# EMIF1 register map
Vendor: Texas Instruments
Peripheral module from a debugger description file (folder omap5430_ES2_PUBLIC).
Registers are 32-bit, read-write, reset 0x0 unless marked. A register's access mark holds for its fields unless they carry their own. Offsets are as the file gives them; lines under a group give offsets from that group; [hi:lo] are bit positions; {n}, {i} and the like mark numbered series; 'fields as' and 'values as' point back to an identical list; <NAME> marks a mode.

## EMIF1 (part 1 of 2)
0x00 EMIF_REVISION ro reset not defined — Revision number register
  [31:0] REVISION — Module revision
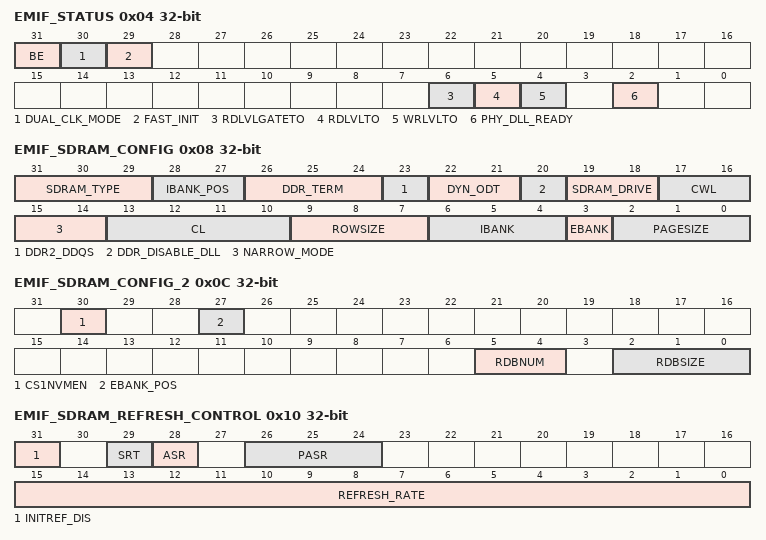
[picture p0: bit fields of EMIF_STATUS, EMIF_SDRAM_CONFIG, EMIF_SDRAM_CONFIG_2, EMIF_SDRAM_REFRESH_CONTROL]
0x04 EMIF_STATUS ro — SDRAM Status Register (STATUS)
  [31] BE — Big endian mode select for 8 and 16-bit devices, set to 1 for big endian or 0 for little endian operation. In current implementation, only 32-bit devices are supported - this bit is don't care.
  [30] DUAL_CLK_MODE — Dual Clock mode. Defines whether the EMIFi_L3_ICLK and EMIF_COREi clock are asynchronous. EMIFi_L3_ICLK and EMIF_COREi clock are asynchronous, if set to 1.
  [29] FAST_INIT — Fast Init. Defines whether the EMIF fast initialization mode has been enabled. Fast initialization is enabled if set to 1.
  [6] RDLVLGATETO — Read DQS Gate Training Timeout. Value of 1 indicates read DQS gate training has timed out because read DQS gate training done was not received from the PHY.
  [5] RDLVLTO — Read Data Eye Training Timeout. Value of 1 indicates read data eye training has timed out because read data eye training done was not received from the PHY.
  [4] WRLVLTO — Write Leveling Timeout. Value of 1 indicates write leveling has timed out because write leveling done was not received from the PHY.
  [2] PHY_DLL_READY — DDR PHY Ready. The DDR PHY is ready for normal operation, if set to 1.
0x08 EMIF_SDRAM_CONFIG — SDRAM Config Register. A write to this register will cause the EMIF to start the SDRAM initialization sequence. For LPDDR2, initialization is only re-started if it was not performed previously because [31] INITREF_DIS was a zero. CAUTION: This register is loaded with values by control module at device reset.
  [31:29] SDRAM_TYPE — SDRAM Type selection. This field is loaded from e-fuse. Set to 3 for DDR3 Set to 4 for LPDDR2 All other values are reserved.
  [28:27] IBANK_POS — Internal bank position. See section , .
  [26:24] DDR_TERM — DDR3 termination resistor value. Set to 0 to disable termination. For DDR3, set to 1 for RZQ/4, set to 2 for RZQ/2, set to 3 for RZQ/6, set to 4 for RZQ/12, and set to 5 for RZQ/8. All other values are reserved.
  [23] DDR2_DDQS — DDR2 differential DDQS enable. NOT SUPPORTED. Set to 1 for compatibility.
  [22:21] DYN_ODT — DDR3 Dynamic ODT. NOT SUPPORTED. Set to 0 to turn off dynamic ODT.
  [20] DDR_DISABLE_DLL — Disable DLL select. Set to 1 to disable DLL inside SDRAM.
  [19:18] SDRAM_DRIVE — SDRAM drive strength.For DDR3, set to 0 for RZQ/6 and set to 1 for RZQ/7. All other values are reserved.
  [17:16] CWL — DDR3 CAS Write latency. Value of 0, 1, 2, and 3 (CAS write latency of 5, 6, 7, and 8) are supported. Use the lowest value supported for best performance. All other values are reserved.
  [15:14] NARROW_MODE — SDRAM data bus width. Set to 0 for 32-bit and set to 1 for 16-bit. All other values are reserved. In the current implementation, only 32-bit devices are supported. Two DDR3 devices are used in parallel to make one 32-bit device.
  [13:10] CL — CAS Latency (referred to as read latency (RL) in some SDRAM specs). The value of this field defines the CAS latency to be used when accessing connected SDRAM devices. Values of 3, 4, 5, 6, 7, and 8 (CAS latency of 3, 4, 5, 6, 7, and 8) are supported for LPDDR2-SDRAM. Values of 2, 4, 6, 8, 10, 12, and 14 (CAS latency of 5, 6, 7, 8, 9, 10, and 11) are supported for DDR3. All other values are reserved. The write latency (WL) is tied to the RL for the LPDDR2. See the LPDDR2 SDRAM standard. Also program the EMIF_DDR_PHY_CONTROL_1[4:0] READ_LATENCY
  [9:7] ROWSIZE — Row Size. Defines the number of row address bits of connected SDRAM devices. Set to 0 for 9 row bits, Set to 1 for 10 row bits, Set to 2 for 11 row bits, Set to 3 for 12 row bits, Set to 4 for 13 row bits, Set to 5 for 14 row bits, Set to 6 for 15 row bits, Set to 7 for 16 row bits. This field is only used when EMIF_SDRAM_CONFIG[28:27] IBANK_POS field is set to 1, 2, or 3 or EBANK_POS field in EMIF_SDRAM_CONFIG_2 register is set to 1.
  [6:4] IBANK — Internal Bank setup. Defines number of banks inside connected SDRAM devices. Set to 0 for 1 bank, Set to 1 for 2 banks, Set to 2 for 4 banks, Set to 3 for 8 banks. All other values are reserved.
  [3] EBANK — External chip select setup. Defines whether SDRAM accesses will use 1 or 2 chip select lines. Set to 0 to use NCS0 only. Set to 1 to use NCS[1:0]. This bit will automatically be set to 0 if EMIF_SDRAM_CONFIG_2[30] CS1NVMEN field is set to 1.
  [2:0] PAGESIZE — Page Size. Defines the internal page size of connected SDRAM devices. Set to 0 for 256-word page (8 column bits), Set to 1 for 512-word page (9 column bits), Set to 2 for 1024-word page (10 column bits), Set to 3 for 2048-word page (11 column bits). All other values are reserved.
0x0C EMIF_SDRAM_CONFIG_2 access per field — SDRAM Config Register 2 CAUTION: This register is loaded with values by control module at device reset.
  [30] CS1NVMEN rw — CS1 LPDDR2-NVM enable. NVMs are not supported at device level.
  [27] EBANK_POS rw — External bank position. Set to 0 to assign external bank address bits from lower OCP address. Set to 1 to assign external bank address bits from higher OCP address bits. See section, .
  [5:4] RDBNUM rw — Row Buffer setup. Defines number of row buffers inside connected LPDDR2-NVM devices. NVM devices are not supported at the device level. Set to 0 for 1 row buffer, set to 1 for 2 row buffers, set to 2 for 4 row buffers, and set to 3 for 8 row buffers. All other values are reserved.
  [2:0] RDBSIZE rw — Row Data Buffer Size. Defines the row data buffer size of connected LPDDR2-NVM devices. NVM devices are not supported at the device level. Set to 0 for 32 bytes, set to 1 for 64 bytes, set to 2 for 128 bytes, set to 3 for 256 bytes, set to 4 for 512 bytes, set to 5 for 1024 bytes, set to 6 for 2048 bytes, and set to 7 for 4096 bytes.
0x10 EMIF_SDRAM_REFRESH_CONTROL access per field — SDRAM Refresh Control Register
  [31] INITREF_DIS rw — Initialization and Refresh disable. When set to 1, EMIF will disable SDRAM initialization and refreshes, but will carry out SDRAM write/read transactions.
  [29] SRT rw — DDR3 Self Refresh temperature range. Set to 0 for normal operating temperature range and set to 1 for extended operating temperature range when the ASR field is set to 0. This bit must be set to 0 if the ASR field is set to 1. A write to this field will cause the EMIF to start the SDRAM initialization sequence.
  [28] ASR rw — DDR3 Auto Self Refresh enable. Set to 1 for auto Self Refresh enable. Set to 0 for manual Self Refresh reference indicated by the SRT field. A write to this field will cause the EMIF to start the SDRAM initialization sequence.
  [26:24] PASR rw — Partial Array Self Refresh. These bits get loaded into the Extended Mode Register of DDR3 during initialization. For DDR3, set to 0 for full array, set to 1 or 5 for 1/2 array, set to 2 or 6 for 1/4 array, set to 3 or 7 for 1/8 array, and set to 4 for 3/4 array to be refreshed. All other values are reserved. A write to this field will cause the EMIF to start the SDRAM initialization sequence.
  [15:0] REFRESH_RATE rw — Refresh Rate. Value in this field is used to define the rate at which connected SDRAM devices will be refreshed. SDRAM refresh rate = REFRESH_RATE / EMIFi_PHY_FICLK. A 533-MHz DDR clock rate system that requires a 7.8 µs refresh rate would need 7.8 × 533 = 4157 or 0x103D value to be written. To avoid lock-up situations, the programmer must not program REFRESH_RATE &lt; (6 × EMIF_SDRAM_TIMING_3[12:4] T_RFC).
0x14 EMIF_SDRAM_REFRESH_CONTROL_SHADOW access per field — SDRAM Refresh Control Shadow Register
  [15:0] REFRESH_RATE_SHDW rw — Shadow field for REFRESH_RATE. This field is loaded intoEMIF_SDRAM_REFRESH_CONTROL[15:0] REFRESH_RATE field when SIdleAck is asserted.
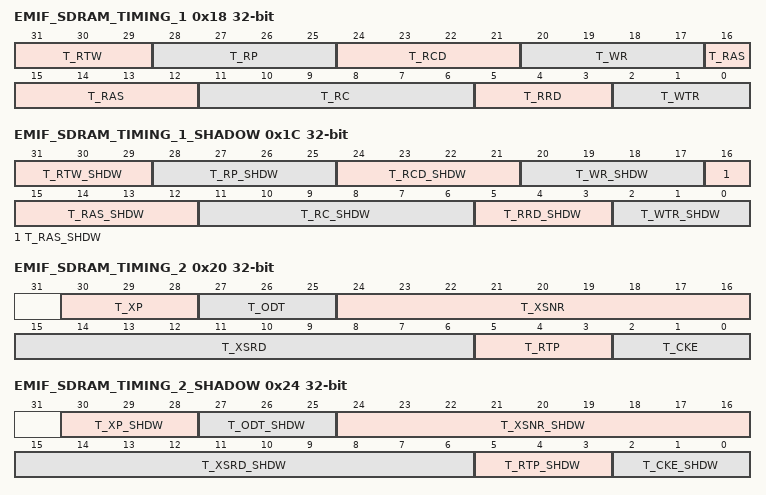
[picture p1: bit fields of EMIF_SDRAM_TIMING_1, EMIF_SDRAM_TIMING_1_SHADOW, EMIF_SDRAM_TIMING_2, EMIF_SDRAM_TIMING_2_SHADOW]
0x18 EMIF_SDRAM_TIMING_1 — SDRAM Timing 1 Register. If this register is byte written, care must be taken that all the fields are written before performing any accesses to the SDRAM.
  [31:29] T_RTW — Minimum number of DDR clock cycles between Read to Write data phases, minus one.
  [28:25] T_RP — Minimum number of DDR clock cycles from Precharge to Activate or Refresh, minus one.
  [24:21] T_RCD — Minimum number of DDR clock cycles from Activate to Read or Write, minus one.
  [20:17] T_WR — Minimum number of DDR clock cycles from last Write transfer to Precharge, minus one.
  [16:12] T_RAS — Minimum number of DDR clock cycles from Activate to Precharge, minus one. T_RAS value needs to be bigger than or equal to T_RDC value.
  [11:6] T_RC — Minimum number of DDR clock cycles from Activate to Activate, minus one.
  [5:3] T_RRD — Minimum number of DDR clock cycles from Activate to Activate for a different bank, minus one. For an 8-bank, this field must be equal to ((tFAW / (4 × tCK)) - 1).
  [2:0] T_WTR — Minimum number of DDR clock cycles from last Write to Read, minus one.
0x1C EMIF_SDRAM_TIMING_1_SHADOW — SDRAM Timing 1 Shadow Register
  [31:29] T_RTW_SHDW — Shadow field for T_RTW. This field is loaded intoEMIF_SDRAM_TIMING_1[31:29] T_RTW field when SIdleAck is asserted.
  [28:25] T_RP_SHDW — Shadow field for T_RP. This field is loaded intoEMIF_SDRAM_TIMING_1[28:25] T_RP field when SIdleAck is asserted.
  [24:21] T_RCD_SHDW — Shadow field for T_RCD. This field is loaded intoEMIF_SDRAM_TIMING_1[24:21] T_RCD field when SIdleAck is asserted.
  [20:17] T_WR_SHDW — Shadow field for T_WR. This field is loaded intoEMIF_SDRAM_TIMING_1[20:17] T_WR field when SIdleAck is asserted.
  [16:12] T_RAS_SHDW — Shadow field for T_RAS. This field is loaded intoEMIF_SDRAM_TIMING_1[16:12] T_RAS field when SIdleAck is asserted.
  [11:6] T_RC_SHDW — Shadow field for T_RC. This field is loaded intoEMIF_SDRAM_TIMING_1[11:6] T_RC field when SIdleAck is asserted.
  [5:3] T_RRD_SHDW — Shadow field for T_RRD. This field is loaded intoEMIF_SDRAM_TIMING_1[5:3] T_RRD field when SIdleAck is asserted.
  [2:0] T_WTR_SHDW — Shadow field for T_WTR. This field is loaded intoEMIF_SDRAM_TIMING_1[2:0] T_WTR field when SIdleAck is asserted.
0x20 EMIF_SDRAM_TIMING_2 access per field — SDRAM Timing 2 Register. If this register is byte written, care must be taken that all the fields are written before performing any accesses to the SDRAM.
  [30:28] T_XP rw — Minimum number of DDR clock cycles from power-down exit to any command other than a read command, minus one.
  [27:25] T_ODT rw — Minimum number of DDR clock cycles from ODT enable to write data driven for DDR3. Must be equal to tAOND.
  [24:16] T_XSNR rw — Minimum number of DDR clock cycles from Self-Refresh exit to any command other than a Read command, minus one. For LPDDR2, T_XSNR and T_XSRD must be programmed with the same value (tXSR). For DDR3, the value of tXS must be programmed.
  [15:6] T_XSRD rw — Minimum number of DDR clock cycles from Self-Refresh exit to a Read command, minus one. For LPDDR2, T_XSNR and T_XSRD must be programmed with the same value (tXSR). For DDR3, the value of tXSDLL must be programmed.
  [5:3] T_RTP rw — Minimum number of DDR clock cycles for the last read command to a Precharge command, minus one.
  [2:0] T_CKE rw — Minimum number of DDR clock cycles between CKE pin changes, minus one.
0x24 EMIF_SDRAM_TIMING_2_SHADOW access per field — SDRAM Timing 2 Shadow Register
  [30:28] T_XP_SHDW rw — Shadow field for T_XP. This field is loaded intoEMIF_SDRAM_TIMING_2[30:28] T_XP field when SIdleAck is asserted.
  [27:25] T_ODT_SHDW rw — Shadow field for T_ODT. This field is loaded into T_ODT field in SDRAM Timing 2 register when SIdleAck is asserted.
  [24:16] T_XSNR_SHDW rw — Shadow field for T_XSNR. This field is loaded intoEMIF_SDRAM_TIMING_2[24:16] T_XSNR field when SIdleAck is asserted.
  [15:6] T_XSRD_SHDW rw — Shadow field for T_XSRD. This field is loaded intoEMIF_SDRAM_TIMING_2[15:6] T_XSRD field when SIdleAck is asserted.
  [5:3] T_RTP_SHDW rw — Shadow field for T_RTP. This field is loaded intoEMIF_SDRAM_TIMING_2[5:3] T_RTP field when SIdleAck is asserted.
  [2:0] T_CKE_SHDW rw — Shadow field for T_CKE. This field is loaded intoEMIF_SDRAM_TIMING_2[2:0] T_CKE field when SIdleAck is asserted.
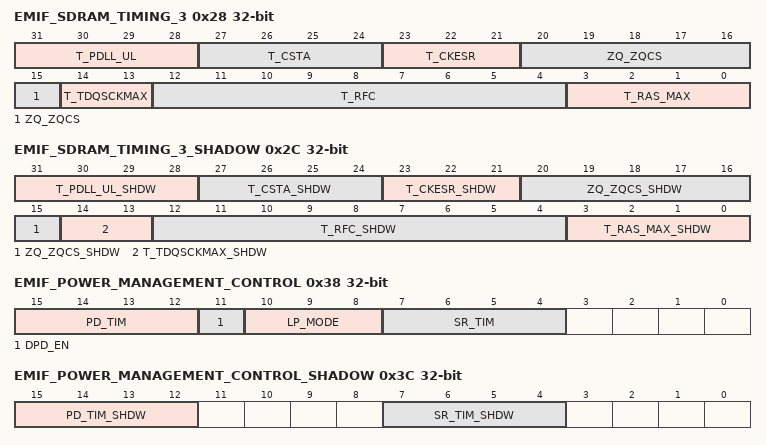
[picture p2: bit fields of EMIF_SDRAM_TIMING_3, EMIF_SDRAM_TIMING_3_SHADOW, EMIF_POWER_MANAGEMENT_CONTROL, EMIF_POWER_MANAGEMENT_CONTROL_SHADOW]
0x28 EMIF_SDRAM_TIMING_3 — SDRAM Timing 3 Register. If this register is byte written, care must be taken that all the fields are written before performing any accesses to the SDRAM.
  [31:28] T_PDLL_UL — Minimum number of DDR clock cycles for PHY DLL to unlock. A value of N will be equal to N x 128 clocks.
  [27:24] T_CSTA — Minimum number of DDR clock cycles between write-to-write or read-to-read data phases to different chip selects, minus one.
  [23:21] T_CKESR — Minimum number of DDR clock cycles for which SDRAM must remain in Self Refresh, minus one.
  [20:15] ZQ_ZQCS — Number of DDR clock cycles for a ZQCS command, minus one.
  [14:13] T_TDQSCKMAX — Number of DDR clock that satisfies tDQSCKmax for LPDDR2, minus one.
  [12:4] T_RFC — Minimum number of DDR clock cycles from Refresh or Load Mode to Refresh or Activate, minus one.
  [3:0] T_RAS_MAX — Maximum number of REFRESH_RATE intervals from Activate to Precharge command. This field must be equal to ((tRASmax / tREFI)-1) rounded down to the next lower integer. Value for T_RAS_MAX can be calculated as follows: If tRASmax = 120 us and tREFI = 15.7 us, then T_RAS_MAX = ((120/15.7)-1) = 6.64. Round down to the next lower integer. Therefore, the programmed value must be 6.
0x2C EMIF_SDRAM_TIMING_3_SHADOW — SDRAM Timing 3 Shadow Register
  [31:28] T_PDLL_UL_SHDW — Shadow field for T_PDLL_UL. This field is loaded into T_PDLL_UL field inEMIF_SDRAM_TIMING_3 register when SIdleAck is asserted.
  [27:24] T_CSTA_SHDW — Shadow field for T_CSTA. This field is loaded into T_CSTA field inEMIF_SDRAM_TIMING_3 register when SIdleAck is asserted.
  [23:21] T_CKESR_SHDW — Shadow field for T_CKESR. This field is loaded into T_CKESR field inEMIF_SDRAM_TIMING_3 register when SIdleAck is asserted.
  [20:15] ZQ_ZQCS_SHDW — Shadow field for ZQ_ZQCS. This field is loaded into ZQ_ZQCS field inEMIF_SDRAM_TIMING_3 register when SIdleAck is asserted.
  [14:13] T_TDQSCKMAX_SHDW — Shadow field for T_TDQSCKMAX. This field is loaded intoEMIF_SDRAM_TIMING_3[14:13] T_TDQSCKMAX field when SIdleAck is asserted.
  [12:4] T_RFC_SHDW — Shadow field for T_RFC. This field is loaded intoEMIF_SDRAM_TIMING_3[12:4] T_RFC when SIdleAck is asserted.
  [3:0] T_RAS_MAX_SHDW — Shadow field for T_RAS_MAX. This field is loaded intoEMIF_SDRAM_TIMING_3[3:0] T_RAS_MAX field when SIdleAck is asserted.
0x38 EMIF_POWER_MANAGEMENT_CONTROL access per field — Power Management Control Register. Updating the *_TIM fields must be followed by at least one access to SDRAM for the new value to take an effect.
  [15:12] PD_TIM rw — Power Management timer for Power-Down. The EMIF will put the external SDRAM in Power-Down mode after the EMIF is idle for these number of DDR clock cycles and if LP_MODE field is set to 4. Set to 0 to immediately enter Power-Down mode. Set to 1 for 16 clocks, set to 2 for 32 clocks, set to 3 for 64 clocks, set to 4 for 128 clocks, set to 5 for 256 clocks, set to 6 for 512 clocks, set to 7 for 1024 clocks, set to 8 for 2048 clocks, set to 9 for 4096 clocks, set to 10 for 8192 clocks, set to 11 for 16384 clocks, set to 12 for 32768 clocks, set to 13 for 65536 clocks, set to 14 for 131072 clocks, and set to 15 for 262144 clocks.
  [11] DPD_EN rw — Deep Power Down enable. Set to 0 for normal operation. Set to 1 to enter deep power-down mode. This mode will override the LP_MODE field setting.
  [10:8] LP_MODE rw — Automatic Power Management enable. Set to 1 for Clock Stop (reserved for the not supported LPDDR1 memories), set to 2 for Self Refresh mode, and set to 4 for Power-Down mode. All other values will disable automatic power management.
  [7:4] SR_TIM rw — Power Management timer for Self Refresh. The EMIF will put the external SDRAM in Self Refresh mode after the EMIF is idle for these number of DDR clock cycles and if LP_MODE field is set to 2. Set to 0 to immediately enter Self Refresh mode. Set to 1 for 16 clocks, set to 2 for 32 clocks, set to 3 for 64 clocks, set to 4 for 128 clocks, set to 5 for 256 clocks, set to 6 for 512 clocks, set to 7 for 1024 clocks, set to 8 for 2048 clocks, set to 9 for 4096 clocks, set to 10 for 8192 clocks, set to 11 for 16384 clocks, set to 12 for 32768 clocks, set to 13 for 65536 clocks, set to 14 for 131072 clocks, and set to 15 for 262144 clocks.
0x3C EMIF_POWER_MANAGEMENT_CONTROL_SHADOW access per field — Power Management Control Shadow Register
  [15:12] PD_TIM_SHDW rw — Shadow field for PD_TIM. This field is loaded into PD_TIM field inEMIF_POWER_MANAGEMENT_CONTROL register when SIdleAck is asserted.
  [7:4] SR_TIM_SHDW rw — Shadow field for SR_TIM. This field is loaded into SR_TIM field inEMIF_POWER_MANAGEMENT_CONTROL register when SIdleAck is asserted.
0x40 EMIF_LPDDR2_MODE_REG_DATA access per field — LPDDR2 Mode Reg Data Register A write to this register will cause a Mode Register write command to be sent to the LPDDR2 device with write data as specified in the VALUE_0 field. The address and chip select are taken from the register. A read to this register will cause a Mode Register read command to be sent to the LPDDR2 device. The address and chip select are taken from the register. The read data will appear in VALUE_0 field.
  [6:0] VALUE_0 rw — Mode register value.
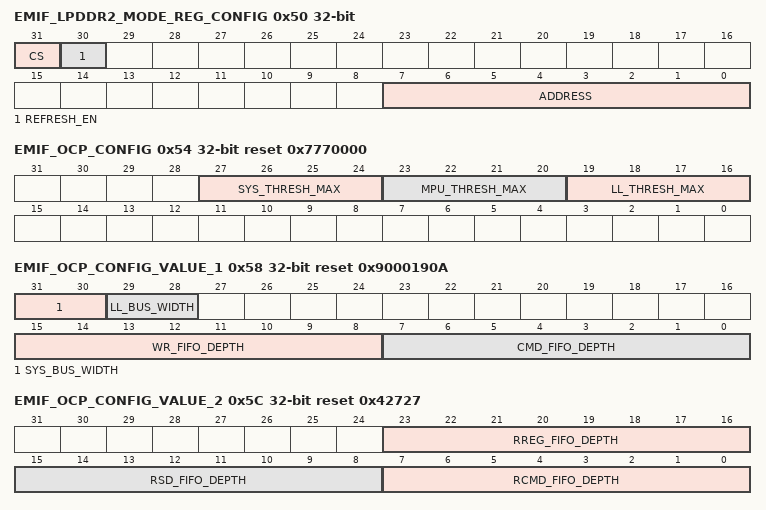
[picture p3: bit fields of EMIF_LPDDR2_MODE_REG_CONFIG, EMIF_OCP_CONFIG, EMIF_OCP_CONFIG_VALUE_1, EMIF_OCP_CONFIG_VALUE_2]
0x50 EMIF_LPDDR2_MODE_REG_CONFIG access per field — LPDDR2 Mode Reg Config Register
  [31] CS rw — Chip select to issue mode register command. Set to 0 for CS0 and set to 1 for CS1.
  [30] REFRESH_EN rw — Refresh Enable after MRW write. If aEMIF_LPDDR2_MODE_REG_DATA register write occurs with this bit set to 1, the refresh operations will commence.
  [7:0] ADDRESS rw — Mode register address.
0x54 EMIF_OCP_CONFIG access per field reset 0x7770000 — OCP Config Register
  [27:24] SYS_THRESH_MAX rw — System OCP Threshold Maximum. The number of commands the system interface can consume in the command FIFO. The value is used to determine when to stop future request, writing a zero will reserve no space for the associated interface. In the event the value is set to zero and a request is seen for that interface, the command FIFO will assume a value of 1. Since the low-latency interface has effectively a higher priority, the only way for the system interface to use all command FIFO entries is to set the LL_THRESH_MAX to zero.
  [23:20] MPU_THRESH_MAX rw — MPU Threshold Maximum. The number of commands the MPU interface can consume in the command FIFO. The value is used to determine when to stop future request, writing a zero will reserve no space for the associated interface. In the event the value is set to zero and a request is seen for that interface, the command FIFO will assume a value of 1. Since the low-latency interface has effectively a higher priority, the only way for the MPU interface to use all command FIFO entries is to set the LL_THRESH_MAX to zero.
  [19:16] LL_THRESH_MAX rw — Low-latency OCP Threshold Maximum. The number of commands the low latency interface can consume in the command FIFO. The value is used to determine when to stop future request, writing a zero will reserve no space for the associated interface. In the event the value is set to zero and a request is seen for that interface, the command FIFO will assume a value of 1.
0x58 EMIF_OCP_CONFIG_VALUE_1 ro reset 0x9000190A — OCP Config Value 1 Register
  [31:30] SYS_BUS_WIDTH — System OCP data bus width 0 = 32-bit wide, 1 = 64-bit wide, 2 = 128-bit wide, 3 = Reserved
  [29:28] LL_BUS_WIDTH — Low-latency OCP data bus width 0 = 32-bit wide, 1 = 64-bit wide, 2 = 128-bit wide, 3 = Reserved
  [15:8] WR_FIFO_DEPTH — Write Data FIFO depth
  [7:0] CMD_FIFO_DEPTH — Command FIFO depth
0x5C EMIF_OCP_CONFIG_VALUE_2 ro reset 0x42727 — OCP Config Value 2 Register
  [23:16] RREG_FIFO_DEPTH — Register Read Data FIFO depth
  [15:8] RSD_FIFO_DEPTH — SDRAM Read Data FIFO depth
  [7:0] RCMD_FIFO_DEPTH — Read Command FIFO depth
0x80 EMIF_PERFORMANCE_COUNTER_1 ro — Performance Counter 1 Register
  [31:0] COUNTER1 — 32-bit counter that can be configured as specified in theEMIF_PERFORMANCE_COUNTER_CONFIG register and EMIF_PERFORMANCE_COUNTER_MASTER_REGION_SELECT register.
0x84 EMIF_PERFORMANCE_COUNTER_2 ro — Performance Counter 2 Register
  [31:0] COUNTER2 — 32-bit counter that can be configured as specified in theEMIF_PERFORMANCE_COUNTER_CONFIG register and EMIF_PERFORMANCE_COUNTER_MASTER_REGION_SELECT register.
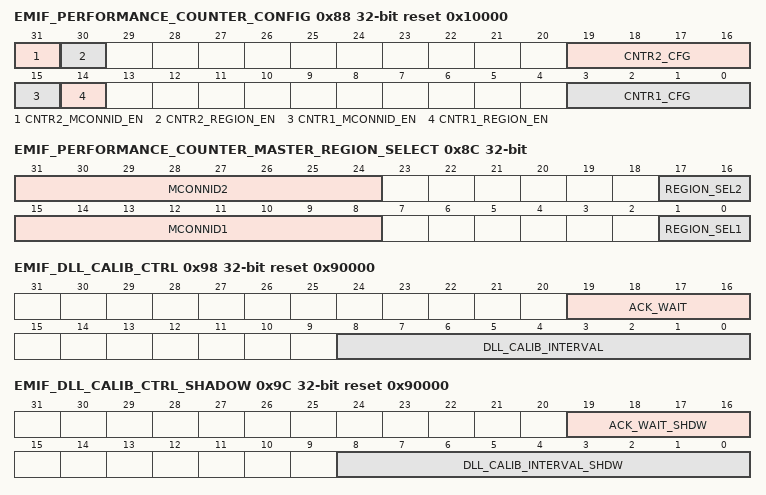
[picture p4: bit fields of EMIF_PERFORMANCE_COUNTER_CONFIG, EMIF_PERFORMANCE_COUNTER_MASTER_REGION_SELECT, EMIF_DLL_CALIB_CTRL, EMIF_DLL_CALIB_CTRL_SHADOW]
0x88 EMIF_PERFORMANCE_COUNTER_CONFIG access per field reset 0x10000 — Performance Counter Config Register
  [31] CNTR2_MCONNID_EN rw — MConnID filter enable forEMIF_PERFORMANCE_COUNTER_2 register.
  [30] CNTR2_REGION_EN rw — Chip Select filter enable forEMIF_PERFORMANCE_COUNTER_2 register.
  [19:16] CNTR2_CFG rw — Filter configuration forEMIF_PERFORMANCE_COUNTER_2. Refer to for details.
  [15] CNTR1_MCONNID_EN rw — MConnID filter enable forEMIF_PERFORMANCE_COUNTER_1 register.
  [14] CNTR1_REGION_EN rw — Chip Select filter enable forEMIF_PERFORMANCE_COUNTER_1 register.
  [3:0] CNTR1_CFG rw — Filter configuration forEMIF_PERFORMANCE_COUNTER_1. Refer to for details.
0x8C EMIF_PERFORMANCE_COUNTER_MASTER_REGION_SELECT access per field — Performance Counter Master Region Select Register The values programmed into the MCONNIDx fields are those in Table ConnID Mapping (Debug View), in , On-Chip Debug Support, left-shifted by 2 bits. For example, to monitor accesses from the IPU subsystem (ConnID = 0x11), the value 0x44 is programmed into the MCONNIDx field.
  [31:24] MCONNID2 rw — MConnID forEMIF_PERFORMANCE_COUNTER_2 register.
  [17:16] REGION_SEL2 rw — MAddrSpace forEMIF_PERFORMANCE_COUNTER_2 register.
  [15:8] MCONNID1 rw — MConnID forEMIF_PERFORMANCE_COUNTER_1 register.
  [1:0] REGION_SEL1 rw — MAddrSpace forEMIF_PERFORMANCE_COUNTER_1 register.
0x90 EMIF_PERFORMANCE_COUNTER_TIME ro — Performance Counter Time Register. This is a free running counter.
  [31:0] TOTAL_TIME — 32-bit counter that continuously counts number for EMIF_COREi clock cycles elapsed after EMIF is brought out of reset.
0x94 EMIF_MISC_REG access per field
  [0] DLL_CALIB_OS rw — Phy_dll_calib one shot : Setting bit to 1 generates a phy_pll_calib pulse. Bit is self cleared when pll_calib gets generated and ack_wait has been satisfied. Software can poll to confirm completion. Uses the EMIF_DLL_CALIB_CTRL[19:16] ACK_WAIT bit field for time to wait after firing off the phy_dll_calib.
0x98 EMIF_DLL_CALIB_CTRL access per field reset 0x90000 — Control register to force idle window time to generate a phy_dll_calib that can be used for updating PHY DLLs during voltage ramps. NOTE: Should always be loaded via the shadow register.
  [19:16] ACK_WAIT rw — The ack_wait determines the required wait time after a phy_dll_calib is generated before another command can be sent. Value program is in terms of EMIF_COREi cycle count. 5 must be the minimum value ever programmed.
  [8:0] DLL_CALIB_INTERVAL rw — This field determines the interval between phy_dll_calib generation. This value is multiplied by a precounter of 16 EMIF_COREi cycles. Program this field one less the value you are targeting; program 1 to achieve interval of 2 (minimum interval supported). Programming zero turns off function. Note the final intervals between dll_calib generation is also a function of ACK_WAIT. Final periodic interval is calculated by: ((DLL_CALIB_INTERVAL + 1) × 16) + ACK_WAIT
0x9C EMIF_DLL_CALIB_CTRL_SHADOW access per field reset 0x90000 — Read Idle Control Shadow Register
  [19:16] ACK_WAIT_SHDW rw — Shadow field for ACK_WAIT. This field is loaded into ACK_WAIT field inEMIF_DLL_CALIB_CTRL register when SIdleAck is asserted
  [8:0] DLL_CALIB_INTERVAL_SHDW rw — Shadow field for DLL_CALIB_INTERVAL. This field is loaded into DLL_CALIB_INTERVAL field in theEMIF_DLL_CALIB_CTRL register when SIdleAck is asserted
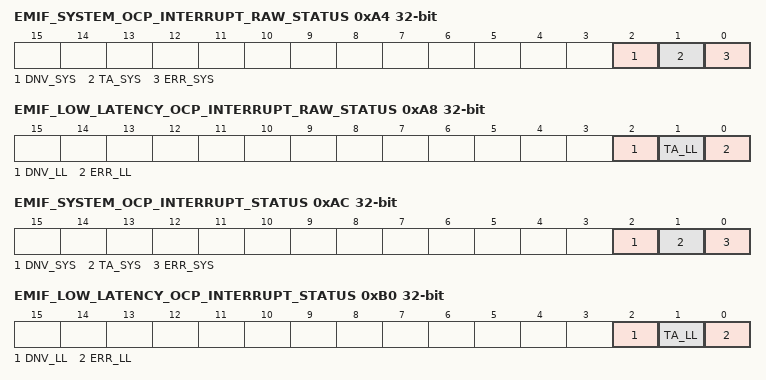
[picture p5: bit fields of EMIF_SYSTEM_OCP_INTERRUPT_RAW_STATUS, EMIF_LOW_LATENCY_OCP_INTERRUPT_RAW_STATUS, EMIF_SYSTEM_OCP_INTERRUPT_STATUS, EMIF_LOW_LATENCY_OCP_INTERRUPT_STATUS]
0xA4 EMIF_SYSTEM_OCP_INTERRUPT_RAW_STATUS access per field — System OCP Interrupt Raw Status Register
  [2] DNV_SYS rw — Raw status of system OCP interrupt for LPDDR2 NVM data not valid. Write 1 to set the (raw) status, typically for debug. Writing 0 has no effect.
  [1] TA_SYS rw — Raw status of system OCP interrupt for SDRAM temperature alert. Write 1 to set the (raw) status, mostly for debug. Writing a 0 has no effect.
  [0] ERR_SYS rw — Raw status of system OCP interrupt for command or address error. Write 1 to set the (raw) status, mostly for debug. Writing a 0 has no effect.
0xA8 EMIF_LOW_LATENCY_OCP_INTERRUPT_RAW_STATUS access per field — Low-Latency OCP Interrupt Raw Status Register
  [2] DNV_LL rw — Raw status of low-latency OCP interrupt for LPDDR2 NVM data not valid. Write 1 to set the (raw) status, typically for debug. Writing 0 has no effect.
  [1] TA_LL rw — Raw status of low-latency OCP interrupt or SDRAM temperature alert. Write 1 to set the (raw) status, mostly for debug. Writing a 0 has no effect.
  [0] ERR_LL rw — Raw status of low-latency OCP interrupt for command or address error. Write 1 to set the (raw) status, mostly for debug. Writing a 0 has no effect.
0xAC EMIF_SYSTEM_OCP_INTERRUPT_STATUS access per field — System OCP Interrupt Status Register
  [2] DNV_SYS rw — Enabled status of system OCP interrupt for LPDDR2 NVM data not valid. Write 1 to clear the status after interrupt is serviced (raw status is cleared; that is, even if not enabled). Writing 0 has no effect.
  [1] TA_SYS rw — Enabled status of system OCP interrupt for SDRAM temperature alert. Write 1 to clear the status after interrupt has been serviced (raw status gets cleared, that is, even if not enabled). Writing a 0 has no effect.
  [0] ERR_SYS rw — Enabled status of system OCP interrupt interrupt for command or address error. Write 1 to clear the status after interrupt has been serviced (raw status gets cleared, that is, even if not enabled). Writing a 0 has no effect.
0xB0 EMIF_LOW_LATENCY_OCP_INTERRUPT_STATUS access per field — Low-Latency OCP Interrupt Status Register
  [2] DNV_LL rw — Enabled status of low-latency OCP interrupt for LPDDR2 NVM data not valid. Write 1 to clear the status after interrupt is serviced (raw status is cleared; that is, even if not enabled). Writing 0 has no effect.
  [1] TA_LL rw — Enabled status of low-latency OCP interrupt for SDRAM temperature alert. Write 1 to clear the status after interrupt has been serviced (raw status gets cleared, that is, even if not enabled). Writing a 0 has no effect.
  [0] ERR_LL rw — Enabled status of low-latency OCP interrupt for command or address error. Write 1 to clear the status after interrupt has been serviced (raw status gets cleared, that is, even if not enabled). Writing a 0 has no effect.
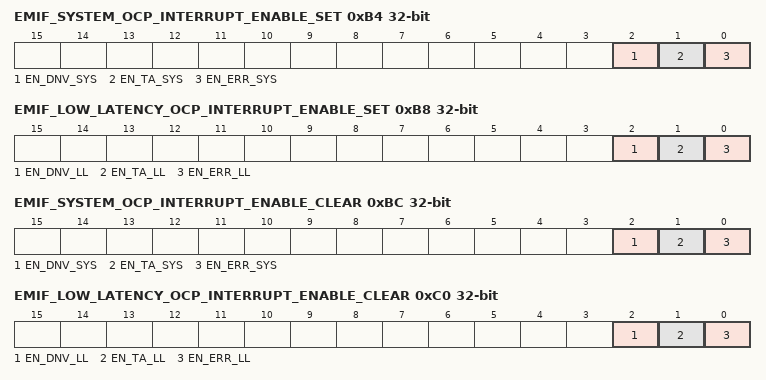
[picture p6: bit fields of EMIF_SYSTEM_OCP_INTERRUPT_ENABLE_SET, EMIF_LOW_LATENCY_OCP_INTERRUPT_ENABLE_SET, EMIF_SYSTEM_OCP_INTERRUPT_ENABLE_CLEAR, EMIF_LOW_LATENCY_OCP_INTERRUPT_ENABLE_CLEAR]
0xB4 EMIF_SYSTEM_OCP_INTERRUPT_ENABLE_SET access not given — System OCP Interrupt Enable Set Register
  [2] EN_DNV_SYS — Enable set for system OCP interrupt for LPDDR2 NVM data not valid. Writing 1 enables the interrupt and sets this bit and the corresponding Interrupt-enable clear register. Writing 0 has no effect. (access RW W1toSet)
  [1] EN_TA_SYS — Enable set for system OCP interrupt for SDRAM temperature alert. . Writing a 1 will enable the interrupt, and set this bit as well as the corresponding Interrupt Enable Clear Register. Writing a 0 has no effect. (access RW W1toSet)
  [0] EN_ERR_SYS — Enable set for system OCP interrupt for command or address error. Writing a 1 will enable the interrupt, and set this bit as well as the corresponding Interrupt Enable Clear Register. Writing a 0 has no effect. (access RW W1toSet)
0xB8 EMIF_LOW_LATENCY_OCP_INTERRUPT_ENABLE_SET access not given — Low-Latency OCP Interrupt Enable Set Register
  [2] EN_DNV_LL — Enable set for low-latency OCP interrupt for LPDDR2 NVM data not valid. Writing 1 enables the interrupt and sets this bit and the corresponding Interrupt-enable clear register. Writing a 0 has no effect. (access RW W1toSet)
  [1] EN_TA_LL — Enable set for low-latency OCP interrupt for SDRAM temperature alert. Writing a 1 will enable the interrupt, and set this bit as well as the corresponding Interrupt Enable Clear Register. Writing a 0 has no effect. (access RW W1toSet)
  [0] EN_ERR_LL — Enable set for low-latency OCP interrupt for command or address error. Writing a 1 will enable the interrupt, and set this bit as well as the corresponding Interrupt Enable Clear Register. Writing a 0 has no effect. (access RW W1toSet)
0xBC EMIF_SYSTEM_OCP_INTERRUPT_ENABLE_CLEAR access not given — System OCP Interrupt Enable Clear Register
  [2] EN_DNV_SYS — Enable clear for system OCP interrupt for LPDDR2 NVM data not valid. Writing 1 disables the interrupt and clears this bit and the corresponding interrupt-enable set register. Writing 0 has no effect. (access RW W1toClr)
  [1] EN_TA_SYS — Enable clear for system OCP interrupt for SDRAM temperature alert. Writing a 1 will disable the interrupt, and clear this bit as well as the corresponding Interrupt Enable Set Register. Writing a 0 has no effect. (access RW W1toClr)
  [0] EN_ERR_SYS — Enable clear for system OCP interrupt for command or address error. Writing a 1 will disable the interrupt, and clear this bit as well as the corresponding Interrupt Enable Set Register. Writing a 0 has no effect. (access RW W1toClr)
0xC0 EMIF_LOW_LATENCY_OCP_INTERRUPT_ENABLE_CLEAR access not given — Low-Latency OCP Interrupt Enable Clear Register
  [2] EN_DNV_LL — Enable clear for low-latency OCP interrupt for LPDDR2 NVM data not valid. Writing 1 disables the interrupt and clears this bit and the corresponding interrupt enable set register. Writing 0 has no effect. (access RW W1toClr)
  [1] EN_TA_LL — Enable clear for low-latency OCP interrupt for SDRAM temperature alert. Writing a 1 will disable the interrupt, and clear this bit as well as the corresponding Interrupt Enable Set Register. Writing a 0 has no effect. (access RW W1toClr)
  [0] EN_ERR_LL — Enable clear for low-latency OCP interrupt for command or address error. Writing a 1 will disable the interrupt, and clear this bit as well as the corresponding Interrupt Enable Set Register. Writing a 0 has no effect. (access RW W1toClr)
